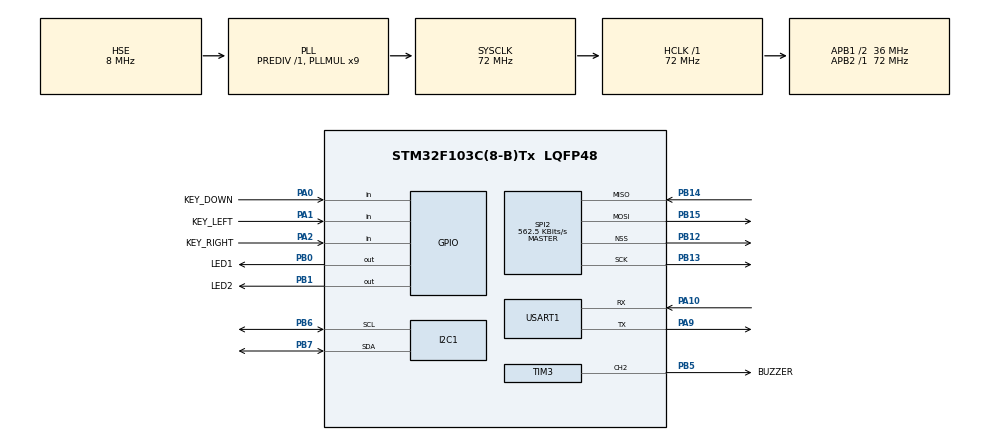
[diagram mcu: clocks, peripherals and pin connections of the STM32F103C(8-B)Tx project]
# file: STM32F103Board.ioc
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Dma.Request0=USART1_RX
Dma.Request1=USART1_TX
Dma.USART1_RX.0.Direction=DMA_PERIPH_TO_MEMORY
Dma.USART1_RX.0.Instance=DMA1_Channel5
Dma.USART1_RX.0.MemDataAlignment=DMA_MDATAALIGN_BYTE
Dma.USART1_RX.0.MemInc=DMA_MINC_ENABLE
Dma.USART1_RX.0.Mode=DMA_NORMAL
Dma.USART1_RX.0.PeriphDataAlignment=DMA_PDATAALIGN_BYTE
Dma.USART1_RX.0.PeriphInc=DMA_PINC_DISABLE
Dma.USART1_RX.0.Priority=DMA_PRIORITY_HIGH
Dma.USART1_TX.1.Direction=DMA_MEMORY_TO_PERIPH
Dma.USART1_TX.1.Instance=DMA1_Channel4
Dma.USART1_TX.1.MemDataAlignment=DMA_MDATAALIGN_BYTE
Dma.USART1_TX.1.MemInc=DMA_MINC_ENABLE
Dma.USART1_TX.1.Mode=DMA_NORMAL
Dma.USART1_TX.1.PeriphDataAlignment=DMA_PDATAALIGN_BYTE
Dma.USART1_TX.1.PeriphInc=DMA_PINC_DISABLE
Dma.USART1_TX.1.Priority=DMA_PRIORITY_HIGH
I2C1.DutyCycle=I2C_DUTYCYCLE_2
I2C1.I2C_Mode=I2C_Fast
Mcu.Family=STM32F1
Mcu.Name=STM32F103C(8-B)Tx
Mcu.Package=LQFP48
NVIC.DMA1_Channel4_IRQn=true\:10\:0\:true\:false\:true\:false\:true\:true
NVIC.DMA1_Channel5_IRQn=true\:10\:0\:true\:false\:true\:false\:true\:true
NVIC.I2C1_ER_IRQn=true\:5\:0\:true\:false\:true\:true\:true\:true
NVIC.PriorityGroup=NVIC_PRIORITYGROUP_4
NVIC.SPI2_IRQn=true\:10\:0\:true\:false\:true\:true\:true\:true
NVIC.TIM4_IRQn=true\:14\:0\:true\:false\:true\:false\:true\:true
NVIC.TimeBase=TIM4_IRQn
NVIC.TimeBaseIP=TIM4
NVIC.USART1_IRQn=true\:10\:0\:true\:false\:true\:false\:true\:true
PA0-WKUP.GPIO_Label=KEY_DOWN
PA0-WKUP.GPIO_PuPd=GPIO_PULLUP
PA0-WKUP.Signal=GPIO_Input
PA1.GPIO_Label=KEY_LEFT
PA1.GPIO_PuPd=GPIO_PULLUP
PA1.Signal=GPIO_Input
PA10.Mode=Asynchronous
PA10.Signal=USART1_RX
PA13.Mode=Serial_Wire
PA13.Signal=SYS_JTMS-SWDIO
PA14.Mode=Serial_Wire
PA14.Signal=SYS_JTCK-SWCLK
PA2.GPIO_Label=KEY_RIGHT
PA2.GPIO_PuPd=GPIO_PULLUP
PA2.Signal=GPIO_Input
PA9.Mode=Asynchronous
PA9.Signal=USART1_TX
PB0.GPIO_Label=LED1
PB0.GPIO_ModeDefaultOutputPP=GPIO_MODE_OUTPUT_PP
PB0.GPIO_PuPd=GPIO_PULLUP
PB0.Signal=GPIO_Output
PB1.GPIO_Label=LED2
PB1.GPIO_PuPd=GPIO_PULLUP
PB1.Signal=GPIO_Output
PB12.Mode=NSS_Signal_Hard_Output
PB12.Signal=SPI2_NSS
PB13.Mode=Full_Duplex_Master
PB13.Signal=SPI2_SCK
PB14.Mode=Full_Duplex_Master
PB14.Signal=SPI2_MISO
PB15.Mode=Full_Duplex_Master
PB15.Signal=SPI2_MOSI
PB5.GPIO_Label=BUZZER
PB5.GPIO_Speed=GPIO_SPEED_FREQ_HIGH
PB5.Signal=S_TIM3_CH2
PB6.Mode=I2C
PB6.Signal=I2C1_SCL
PB7.Mode=I2C
PB7.Signal=I2C1_SDA
PD0-OSC_IN.Mode=HSE-External-Oscillator
PD0-OSC_IN.Signal=RCC_OSC_IN
PD1-OSC_OUT.Mode=HSE-External-Oscillator
PD1-OSC_OUT.Signal=RCC_OSC_OUT
ProjectManager.HeapSize=0x400
ProjectManager.StackSize=0x400
ProjectManager.TargetToolchain=CMake
RCC.AHBFreq_Value=72000000
RCC.APB1CLKDivider=RCC_HCLK_DIV2
RCC.APB1Freq_Value=36000000
RCC.APB1TimFreq_Value=72000000
RCC.APB2Freq_Value=72000000
RCC.APB2TimFreq_Value=72000000
RCC.HCLKFreq_Value=72000000
RCC.PLLMUL=RCC_PLL_MUL9
RCC.PLLSourceVirtual=RCC_PLLSOURCE_HSE
RCC.SYSCLKFreq_VALUE=72000000
RCC.SYSCLKSource=RCC_SYSCLKSOURCE_PLLCLK
RCC.USBFreq_Value=72000000
SH.S_TIM3_CH2.0=TIM3_CH2,PWM Generation2 CH2
SPI2.BaudRatePrescaler=SPI_BAUDRATEPRESCALER_64
SPI2.CalculateBaudRate=562.5 KBits/s
SPI2.DataSize=SPI_DATASIZE_8BIT
SPI2.Direction=SPI_DIRECTION_2LINES
SPI2.Mode=SPI_MODE_MASTER
SPI2.VirtualNSS=VM_NSSHARD
SPI2.VirtualType=VM_MASTER
TIM3.Channel-PWM\ Generation2\ CH2=TIM_CHANNEL_2
USART1.VirtualMode=VM_ASYNC
VP_SYS_VS_tim4.Mode=TIM4
board=custom

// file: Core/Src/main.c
/* USER CODE BEGIN Header */
/**
  ******************************************************************************
  * @file           : main.c
  * @brief          : Main program body
  ******************************************************************************
  * @attention
  *
  * Copyright (c) 2026 STMicroelectronics.
  * All rights reserved.
  *
  * This software is licensed under terms that can be found in the LICENSE file
  * in the root directory of this software component.
  * If no LICENSE file comes with this software, it is provided AS-IS.
  *
  ******************************************************************************
  */
/* USER CODE END Header */
#include "main.h"
#include "dma.h"
#include "i2c.h"
#include "spi.h"
#include "tim.h"
#include "usart.h"
#include "gpio.h"

/* USER CODE BEGIN Includes */
#include "task.h"
/* USER CODE END Includes */

void SystemClock_Config(void);

int main(void)
{

  /* MCU Configuration--------------------------------------------------------*/

  /* Reset of all peripherals, Initializes the Flash interface and the Systick. */
  HAL_Init();

  /* Configure the system clock */
  SystemClock_Config();

  /* Initialize all configured peripherals */
  MX_GPIO_Init();
  MX_DMA_Init();
  MX_SPI2_Init();
  MX_TIM3_Init();
  MX_USART1_UART_Init();
  MX_I2C1_Init();
  /* USER CODE BEGIN 2 */
  MainTask();
  /* USER CODE END 2 */

  /* Infinite loop */
  while (1)
  {

  }
}

void SystemClock_Config(void)
{
  RCC_OscInitTypeDef RCC_OscInitStruct = {0};
  RCC_ClkInitTypeDef RCC_ClkInitStruct = {0};

  /** Initializes the RCC Oscillators according to the specified parameters
  * in the RCC_OscInitTypeDef structure.
  */
  RCC_OscInitStruct.OscillatorType = RCC_OSCILLATORTYPE_HSE;
  RCC_OscInitStruct.HSEState = RCC_HSE_ON;
  RCC_OscInitStruct.HSEPredivValue = RCC_HSE_PREDIV_DIV1;
  RCC_OscInitStruct.HSIState = RCC_HSI_ON;
  RCC_OscInitStruct.PLL.PLLState = RCC_PLL_ON;
  RCC_OscInitStruct.PLL.PLLSource = RCC_PLLSOURCE_HSE;
  RCC_OscInitStruct.PLL.PLLMUL = RCC_PLL_MUL9;
  if (HAL_RCC_OscConfig(&RCC_OscInitStruct) != HAL_OK)
  {
    Error_Handler();
  }

  /** Initializes the CPU, AHB and APB buses clocks
  */
  RCC_ClkInitStruct.ClockType = RCC_CLOCKTYPE_HCLK|RCC_CLOCKTYPE_SYSCLK
                              |RCC_CLOCKTYPE_PCLK1|RCC_CLOCKTYPE_PCLK2;
  RCC_ClkInitStruct.SYSCLKSource = RCC_SYSCLKSOURCE_PLLCLK;
  RCC_ClkInitStruct.AHBCLKDivider = RCC_SYSCLK_DIV1;
  RCC_ClkInitStruct.APB1CLKDivider = RCC_HCLK_DIV2;
  RCC_ClkInitStruct.APB2CLKDivider = RCC_HCLK_DIV1;

  if (HAL_RCC_ClockConfig(&RCC_ClkInitStruct, FLASH_LATENCY_2) != HAL_OK)
  {
    Error_Handler();
  }
}

void HAL_TIM_PeriodElapsedCallback(TIM_HandleTypeDef *htim)
{
  if (htim->Instance == TIM4)
  {
    HAL_IncTick();
  }
}

void Error_Handler(void)
{
  __disable_irq();
  while (1)
  {
  }
}
